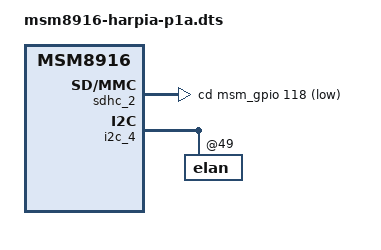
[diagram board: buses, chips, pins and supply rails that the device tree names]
/* Copyright (c) 2014, Motorola Mobility LLC. All rights reserved.
*
* This program is free software; you can redistribute it and/or modify
* it under the terms of the GNU General Public License version 2 and
* only version 2 as published by the Free Software Foundation.
*
* This program is distributed in the hope that it will be useful,
* but WITHOUT ANY WARRANTY; without even the implied warranty of
* MERCHANTABILITY or FITNESS FOR A PARTICULAR PURPOSE.  See the
* GNU General Public License for more details.
*/

/dts-v1/;

#include "msm8916-harpia.dtsi"
/ {
	qcom,board-id = <0x4D 0x81A0>;
};

/*chris over-ride sdcard hotplug cd pin*/
&tlmm_pinmux {
        sdhc2_cd_pin {
               qcom,pins = <&gp 118>;
        };
};

/*chris over-ride sdcard hotplug cd pin*/
&sdhc_2 {
        interrupt-map = <0 &intc 0 125 0
                        1 &intc 0 221 0
                        2 &msm_gpio 118 0>;
        cd-gpios = <&msm_gpio 118 0x1>;
};
&i2c_4 { /* BLSP1 QUP4 on dvt1a/dvt1b */
	elan@49 {
		epl,wait_time = <0x09>;
		epl,dt_st_gain = <9>;
		epl,als_c_gain = <100>;
		epl,ps_eg_sign = <1>;
		epl,ps_intt = <5>;
		epl,ps_gain = <0x01>;
		epl,ps_cycle = <0x04>;
		epl,ps_ir_drive = <0x02>;
		epl,ps_low_threshold = <9200>;
		epl,ps_high_threshold = <10000>;
		epl,ps_max_ct = <10000>;
		epl,ps_dyn_l_offset = <900>;
		epl,ps_dyn_h_offset = <1700>;
		epl,ps_rs = <0>;
	};
};
